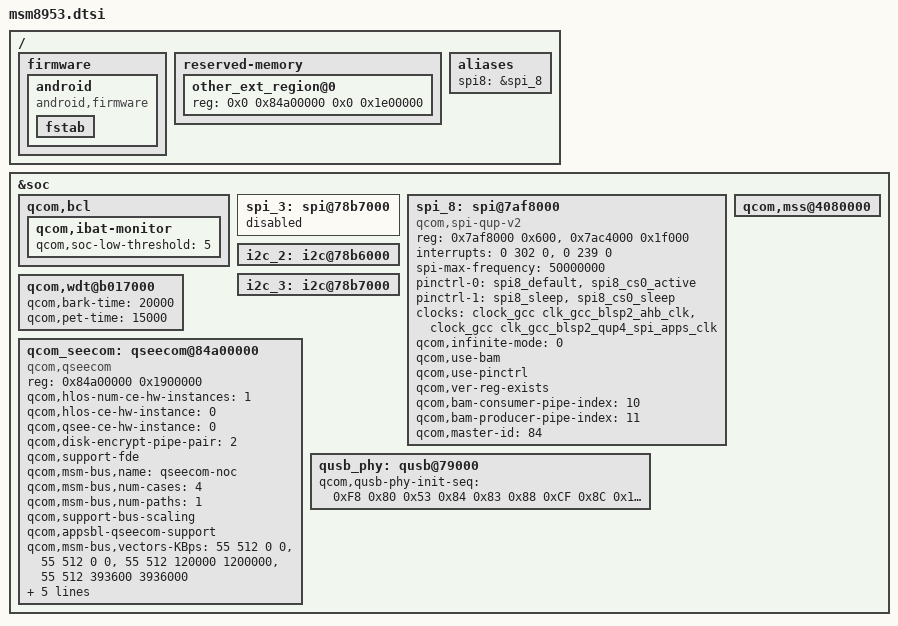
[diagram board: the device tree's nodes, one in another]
/*
 * Copyright (c) 2015-2016, The Linux Foundation. All rights reserved.
 *
 * This program is free software; you can redistribute it and/or modify
 * it under the terms of the GNU General Public License version 2 and
 * only version 2 as published by the Free Software Foundation.
 *
 * This program is distributed in the hope that it will be useful,
 * but WITHOUT ANY WARRANTY; without even the implied warranty of
 * MERCHANTABILITY or FITNESS FOR A PARTICULAR PURPOSE.  See the
 * GNU General Public License for more details.
 */

/ {

	firmware: firmware {
                android {
                        compatible = "android,firmware";
                        fstab {
                                /delete-node/ vendor;
                        };
                };
        };
	reserved-memory {
		other_ext_region@0 {
			reg = <0x0 0x84a00000 0x0 0x1e00000>;
		};
	};

	aliases {
		spi8 = &spi_8;//ZTEMT: fengxun added for AL3200
	};


};

&soc {

	qcom,bcl {
		qcom,ibat-monitor {
			qcom,soc-low-threshold = <5>;
		};
	};



	spi_3: spi@78b7000 { /* BLSP1 QUP3 */
		//ztemt: disable fp spi on ap
		status = "disabled";
	};
//ZTEMT: fengxun added for AL3200 ---start
	spi_8: spi@7af8000 { 
		compatible = "qcom,spi-qup-v2";
		#address-cells = <1>;
		#size-cells = <0>;
		reg-names = "spi_physical", "spi_bam_physical";
		reg = <0x7af8000 0x600>,
			<0x7ac4000 0x1f000>;
		interrupt-names = "spi_irq", "spi_bam_irq";
		interrupts = <0 302 0>, <0 239 0>;
		spi-max-frequency = <50000000>;
		pinctrl-names = "spi_default", "spi_sleep";
		pinctrl-0 = <&spi8_default &spi8_cs0_active>;
		pinctrl-1 = <&spi8_sleep &spi8_cs0_sleep>;
		clocks = <&clock_gcc clk_gcc_blsp2_ahb_clk>,
			<&clock_gcc clk_gcc_blsp2_qup4_spi_apps_clk>;
		clock-names = "iface_clk", "core_clk";
		qcom,infinite-mode = <0>;
		qcom,use-bam;
		qcom,use-pinctrl;
		qcom,ver-reg-exists;
		qcom,bam-consumer-pipe-index = <10>;
		qcom,bam-producer-pipe-index = <11>;
		qcom,master-id = <84>;
		status = "ok";
	};
//ZTEMT: fengxun added for AL3200 ---end
	i2c_2: i2c@78b6000 { /* BLSP1 QUP2 */
		/* DSI_TO_HDMI I2C configuration */
		/delete-node/ adv7533@39;
	};

	i2c_3: i2c@78b7000 { /* BLSP1 QUP3 */
		status = "okay";
	};

	qcom,wdt@b017000 {
		qcom,bark-time = <20000>;
		qcom,pet-time = <15000>;
	};

	/delete-node/ qseecom@85b00000;
	qcom_seecom: qseecom@84a00000 {
		compatible = "qcom,qseecom";
		reg = <0x84a00000 0x1900000>;
		reg-names = "secapp-region";
		qcom,hlos-num-ce-hw-instances = <1>;
		qcom,hlos-ce-hw-instance = <0>;
		qcom,qsee-ce-hw-instance = <0>;
		qcom,disk-encrypt-pipe-pair = <2>;
		qcom,support-fde;
		qcom,msm-bus,name = "qseecom-noc";
		qcom,msm-bus,num-cases = <4>;
		qcom,msm-bus,num-paths = <1>;
		qcom,support-bus-scaling;
		qcom,appsbl-qseecom-support;
		qcom,msm-bus,vectors-KBps =
			<55 512 0 0>,
			<55 512 0 0>,
			<55 512 120000 1200000>,
			<55 512 393600 3936000>;
		clocks = <&clock_gcc clk_crypto_clk_src>,
			 <&clock_gcc clk_gcc_crypto_clk>,
			 <&clock_gcc clk_gcc_crypto_ahb_clk>,
			 <&clock_gcc clk_gcc_crypto_axi_clk>;
		clock-names = "core_clk_src", "core_clk",
				"iface_clk", "bus_clk";
		qcom,ce-opp-freq = <100000000>;
	};

	qcom,mss@4080000 {
		/delete-property/ qcom,pas-id;
		/delete-property/ qcom,pil-mss-memsetup;
	};


	qusb_phy: qusb@79000 {
		qcom,qusb-phy-init-seq = <0xF8 0x80
					0x53 0x84
					0x83 0x88
					0xCF 0x8C
					0x14 0x9C
					0x30 0x08
					0x79 0x0C
					0x21 0x10
					0x00 0x90
					0x9F 0x1C
					0x00 0x18>;

	};

	/delete-node/ uart@7aef000;
};




